# MIMXRT1064 register map
Vendor: nxp.com; File version: 1.0
CPU: CM7 r0p1, little endian, MPU, FPU, VTOR, 4 interrupt priority bits
Registers are 32-bit, read-write, reset 0x0 unless marked. A register's access mark holds for its fields unless they carry their own. Offsets are from the block's base; [hi:lo] are bit positions; {n}, {i} and the like mark numbered series; 'fields as' and 'values as' point back to an identical list.

## SEMC
Base 0x402F0000
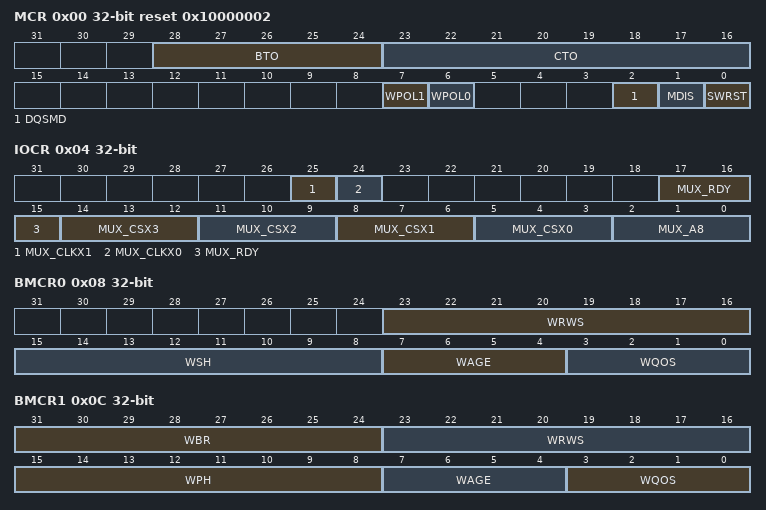
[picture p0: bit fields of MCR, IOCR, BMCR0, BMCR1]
0x00 MCR reset 0x10000002 — Module Control Register
  [28:24] BTO — Bus timeout cycles
    0=255*1; 1=255*2; 31=255*231
  [23:16] CTO — Command Execution timeout cycles
  [7] WPOL1 — R/B# polarity for NAND device
    0=R/B# polarity is not changed; 1=R/B# polarity is inverted
  [6] WPOL0 — WAIT/RDY polarity for SRAM/NOR
    0=WAIT/RDY polarity is not changed; 1=WAIT/RDY polarity is inverted
  [2] DQSMD — DQS (read strobe) mode
    0=Dummy read strobe loopbacked internally; 1=Dummy read strobe loopbacked from DQS pad
  [1] MDIS — Module Disable
    0=Module enabled; 1=Module disabled
  [0] SWRST — Software Reset
    0=No reset; 1=Reset
0x04 IOCR — IO MUX Control Register
  [25] MUX_CLKX1 — SEMC_CLKX1 function selection
    0=NOR clock; 1=SRAM clock
  [24] MUX_CLKX0 — SEMC_CLKX0 function selection
    0=NOR clock; 1=SRAM clock
  [17:15] MUX_RDY — SEMC_RDY function selection
    0=NAND R/B# input; 1=SDRAM CS1; 2=SDRAM CS2; 3=SDRAM CS3; 4=NOR CE#; 5=SRAM CE#; 6=DBI CSX
  [3n+5:3n+3] MUX_CSX{n} (n=0..3) — SEMC_CSX{n} output selection
    1=SDRAM CS1; 2=SDRAM CS2; 3=SDRAM CS3; 4=NAND CE#; 5=NOR CE#; 6=SRAM CE#; 7=DBI CSX
  [2:0] MUX_A8 — SEMC_ADDR08 output selection
    0=SDRAM Address bit 8 (A8) or NOR/SRAM Address bit 24 (A24) in ADMUX 16bit mode; 1=NAND CE#; 2=NOR CE#; 3=SRAM CE#; 4=DBI CSX; 5=SDRAM Address bit 8 (A8) or NOR/SRAM Address bit 24 (A24) in ADMUX 16bit mode; 6=SDRAM Address bit 8 (A8) or NOR/SRAM Address bit 24 (A24) in ADMUX 16bit mode; 7=SDRAM Address bit 8 (A8) or NOR/SRAM Address bit 24 (A24) in ADMUX 16bit mode
0x08 BMCR0 — Bus (AXI) Master Control Register 0
  [23:16] WRWS — Weight of slave hit with Read/Write Switch
  [15:8] WSH — Weight of Slave Hit without read/write switch
  [7:4] WAGE — Weight of AGE
  [3:0] WQOS — Weight of QOS
0x0C BMCR1 — Bus (AXI) Master Control Register 1
  [31:24] WBR — Weight of Bank Rotation
  [23:16] WRWS — Weight of slave hit without Read/Write Switch
  [15:8] WPH — Weight of Page Hit
  [7:4] WAGE — Weight of AGE
  [3:0] WQOS — Weight of QOS
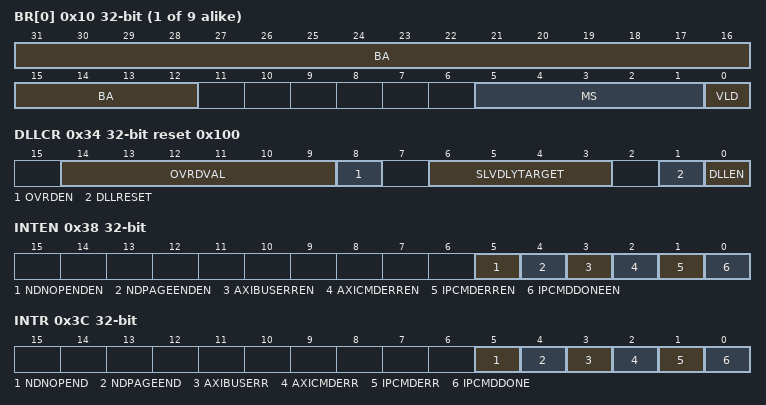
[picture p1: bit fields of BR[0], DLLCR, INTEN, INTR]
{0x10+4i} BR[{i}] (i=0..8) — Base Register n
  [31:12] BA — Base Address
  [5:1] MS — Memory size
    0=4KB; 1=8KB; 2=16KB; 3=32KB; 4=64KB; 5=128KB; 6=256KB; 7=512KB; 8=1MB; 9=2MB; 10=4MB; 11=8MB; 12=16MB; 13=32MB; 14=64MB; 15=128MB; 16=256MB; 17=512MB; 18=1GB; 19=2GB; {v}=4GB (v=20..31)
  [0] VLD — Valid
    0=The memory is invalid, can not be accessed; 1=The memory is valid, can be accessed
0x34 DLLCR reset 0x100 — DLL Control Register
  [14:9] OVRDVAL — Override Value
  [8] OVRDEN — Override Enable
    0=The delay cell number is not overridden; 1=The delay cell number is overridden
  [6:3] SLVDLYTARGET — Delay Target for Slave
  [1] DLLRESET
    0=DLL is not reset; 1=DLL is reset
  [0] DLLEN — DLL calibration enable
    0=DLL calibration is disabled; 1=DLL calibration is enabled
0x38 INTEN — Interrupt Enable Register
  [all] fields
    0=Interrupt is disabled; 1=Interrupt is enabled
  [5] NDNOPENDEN — NAND no pending AXI access interrupt enable
  [4] NDPAGEENDEN — NAND page end interrupt enable
  [3] AXIBUSERREN — AXI bus error interrupt enable
  [2] AXICMDERREN — AXI command error interrupt enable
  [1] IPCMDERREN — IP command error interrupt enable
  [0] IPCMDDONEEN — IP command done interrupt enable
0x3C INTR write-1-clears — Interrupt Register
  [5] NDNOPEND write-1-clears — NAND no pending AXI write transaction interrupt
    0=At least one NAND AXI write transaction is pending or no NAND write transaction is sent to the queue; 1=All NAND AXI write pending transactions are finished
  [4] NDPAGEEND write-1-clears — NAND page end interrupt
    0=The last address of main space in the NAND is not written by AXI command; 1=The last address of main space in the NAND is written by AXI command
  [3] AXIBUSERR write-1-clears — AXI bus error interrupt
    0=No AXI bus error; 1=AXI bus error occurs
  [2] AXICMDERR write-1-clears — AXI command error interrupt
    0=No AXI command error; 1=AXI command error occurs
  [1] IPCMDERR write-1-clears — IP command error done interrupt
    0=No IP command error; 1=IP command error occurs
  [0] IPCMDDONE write-1-clears — IP command normal done interrupt
    0=IP command is not done; 1=IP command is done
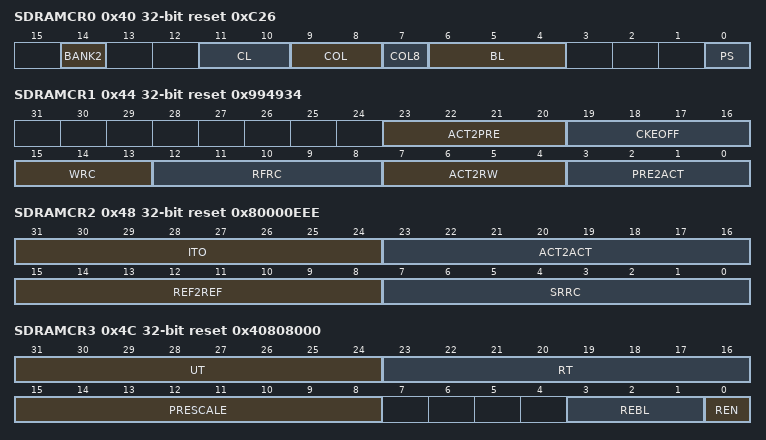
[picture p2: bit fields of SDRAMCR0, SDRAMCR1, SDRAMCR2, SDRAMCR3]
0x40 SDRAMCR0 reset 0xC26 — SDRAM Control Register 0
  [14] BANK2 — 2 Bank selection bit
    0=SDRAM device has 4 banks; 1=SDRAM device has 2 banks
  [11:10] CL — CAS Latency
    0=1; 1=1; 2=2; 3=3
  [9:8] COL — Column address bit number
    0=12; 1=11; 2=10; 3=9
  [7] COL8 — Column 8 selection
    0=Column address bit number is decided by COL field; 1=Column address bit number is 8. COL field is ignored.
  [6:4] BL — Burst Length
    0=1; 1=2; 2=4; {v}=8 (v=3..7)
  [0] PS — Port Size
    0=8bit; 1=16bit
0x44 SDRAMCR1 reset 0x994934 — SDRAM Control Register 1
  [23:20] ACT2PRE — ACTIVE to PRECHARGE minimum time
  [19:16] CKEOFF — CKE off minimum time
  [15:13] WRC — WRITE recovery time
  [12:8] RFRC — REFRESH recovery time
  [7:4] ACT2RW — ACTIVE to READ/WRITE delay
  [3:0] PRE2ACT — PRECHARGE to ACTIVE/REFRESH command wait time
0x48 SDRAMCR2 reset 0x80000EEE — SDRAM Control Register 2
  [31:24] ITO — SDRAM idle timeout
    0=IDLE timeout period is 256*Prescale period; {v}=IDLE timeout period is ITO*Prescale period (v=1..9)
  [23:16] ACT2ACT — ACTIVE to ACTIVE delay
  [15:8] REF2REF — REFRESH to REFRESH delay
  [7:0] SRRC — SELF REFRESH recovery time
0x4C SDRAMCR3 reset 0x40808000 — SDRAM Control Register 3
  [31:24] UT — Urgent refresh threshold
    0=256*(Prescaler period); {v}=UT*(Prescaler period) (v=1..9)
  [23:16] RT — Refresh timer period
    0=(256+1)*(Prescaler period); {v}=(RT+1)*(Prescaler period) (v=1..9)
  [15:8] PRESCALE — Prescaler period
    0=(256*16+1) clock cycles; {v}=(PRESCALE*16+1) clock cycles (v=1..9)
  [3:1] REBL — Refresh burst length
    {v}={v+1} (v=0..7)
  [0] REN — Refresh enable
    0=The SEMC does not send AUTO REFRESH command automatically; 1=The SEMC sends AUTO REFRESH command automatically
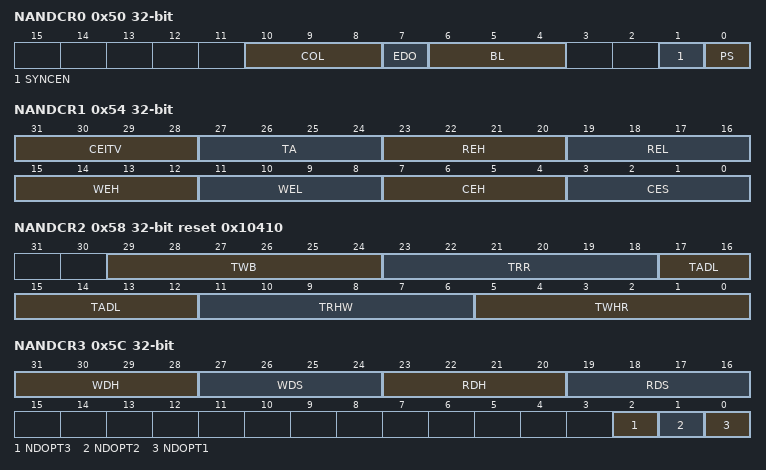
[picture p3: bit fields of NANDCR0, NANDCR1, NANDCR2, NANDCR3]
0x50 NANDCR0 — NAND Control Register 0
  [10:8] COL — Column address bit number
    0=16; 1=15; 2=14; 3=13; 4=12; 5=11; 6=10; 7=9
  [7] EDO — EDO mode enabled
    0=EDO mode disabled; 1=EDO mode enabled
  [6:4] BL — Burst Length
    0=1; 1=2; 2=4; 3=8; 4=16; 5=32; 6=64; 7=64
  [1] SYNCEN — Synchronous Mode Enable
    0=Asynchronous mode is enabled; 1=Synchronous mode is enabled
  [0] PS — Port Size
    0=8bit; 1=16bit
0x54 NANDCR1 — NAND Control Register 1
  [31:28] CEITV — CE# interval time
  [27:24] TA — Turnaround time
  [23:20] REH — RE# high time
  [19:16] REL — RE# low time
  [15:12] WEH — WE# high time
  [11:8] WEL — WE# low time
  [7:4] CEH — CE# hold time
  [3:0] CES — CE# setup time
0x58 NANDCR2 reset 0x10410 — NAND Control Register 2
  [29:24] TWB — WE# high to busy time
  [23:18] TRR — Ready to RE# low time
  [17:12] TADL — Address cycle to data loading time
  [11:6] TRHW — RE# high to WE# low time
  [5:0] TWHR — WE# high to RE# low time
0x5C NANDCR3 — NAND Control Register 3
  [31:28] WDH — Write Data Hold time
  [27:24] WDS — Write Data Setup time
  [23:20] RDH — Read Data Hold time
  [19:16] RDS — Read Data Setup time
  [2] NDOPT3 — NAND option bit 3
  [1] NDOPT2 — NAND option bit 2
  [0] NDOPT1 — NAND option bit 1
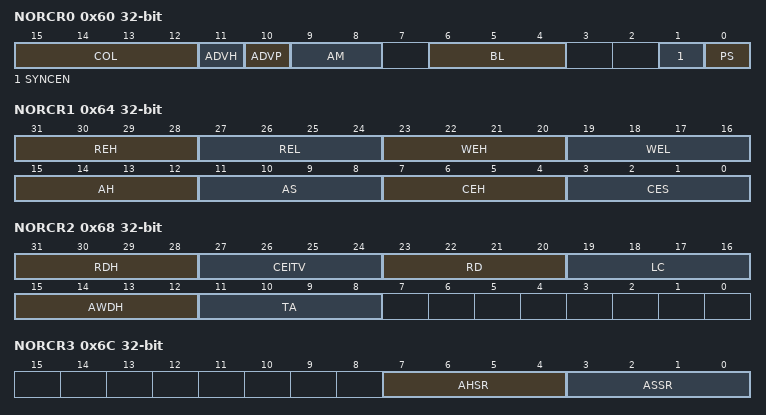
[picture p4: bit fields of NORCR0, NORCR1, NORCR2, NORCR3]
0x60 NORCR0 — NOR Control Register 0
  [15:12] COL — Column Address bit width
    0=12 Bits; 1=11 Bits; 2=10 Bits; 3=9 Bits; 4=8 Bits; 5=7 Bits; 6=6 Bits; 7=5 Bits; 8=4 Bits; 9=3 Bits; 10=2 Bits; {v}=12 Bits (v=11..15)
  [11] ADVH — ADV# level control during address hold state
    0=ADV# is high during address hold state; 1=ADV# is low during address hold state
  [10] ADVP — ADV# Polarity
    0=ADV# is active low; 1=ADV# is active high
  [9:8] AM — Address Mode
    0=Address/Data MUX mode (ADMUX); 1=Advanced Address/Data MUX mode (AADM)
  [6:4] BL — Burst Length
    0=1; 1=2; 2=4; 3=8; 4=16; 5=32; 6=64; 7=64
  [1] SYNCEN — Synchronous Mode Enable
    0=Asynchronous mode is enabled; 1=Synchronous mode is enabled. Only fixed latency mode is supported.
  [0] PS — Port Size
    0=8bit; 1=16bit
0x64 NORCR1 — NOR Control Register 1
  [31:28] REH — RE high time
  [27:24] REL — RE low time
  [23:20] WEH — WE high time
  [19:16] WEL — WE low time
  [15:12] AH — Address hold time
  [11:8] AS — Address setup time
  [7:4] CEH — CE hold time
  [3:0] CES — CE setup time
0x68 NORCR2 — NOR Control Register 2
  [31:28] RDH — Read hold time
  [27:24] CEITV — CE# interval time
  [23:20] RD — Read time
  [19:16] LC — Latency count
  [15:12] AWDH — Address to write data hold time
  [11:8] TA — Turnaround time
0x6C NORCR3 — NOR Control Register 3
  [7:4] AHSR — Address hold time for SYNC read
  [3:0] ASSR — Address setup time for SYNC read
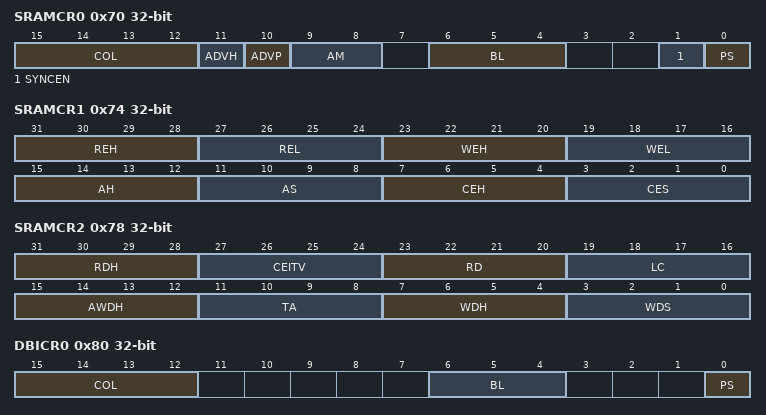
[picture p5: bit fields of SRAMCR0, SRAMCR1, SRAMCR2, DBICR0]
0x70 SRAMCR0 — SRAM Control Register 0
  [15:12] COL — Column Address bit width
    values as NORCR0.COL
  [11] ADVH — ADV# level control during address hold state
    values as NORCR0.ADVH
  [10] ADVP — ADV# polarity
    0=ADV# is active low; 1=ADV# is active high
  [9:8] AM — Address Mode
    values as NORCR0.AM
  [6:4] BL — Burst Length
    0=1; 1=2; 2=4; 3=8; 4=16; 5=32; 6=64; 7=64
  [1] SYNCEN — Synchronous Mode Enable
    values as NORCR0.SYNCEN
  [0] PS — Port Size
    0=8bit; 1=16bit
0x74 SRAMCR1 — SRAM Control Register 1
  fields as NORCR1
0x78 SRAMCR2 — SRAM Control Register 2
  [31:28] RDH — Read hold time
  [27:24] CEITV — CE# interval time
  [23:20] RD — Read time
  [19:16] LC — Latency count
  [15:12] AWDH — Address to write data hold time
  [11:8] TA — Turnaround time
  [7:4] WDH — Write Data hold time
  [3:0] WDS — Write Data setup time
0x7C SRAMCR3 — SRAM Control Register 3
0x80 DBICR0 — DBI-B Control Register 0
  [15:12] COL — Column Address bit width
    values as NORCR0.COL
  [6:4] BL — Burst Length
    0=1; 1=2; 2=4; 3=8; 4=16; 5=32; 6=64; 7=64
  [0] PS — Port Size
    0=8bit; 1=16bit
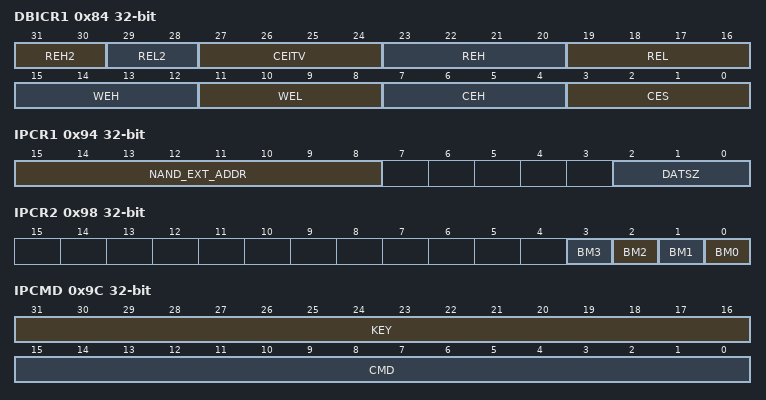
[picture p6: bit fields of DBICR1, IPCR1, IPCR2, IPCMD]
0x84 DBICR1 — DBI-B Control Register 1
  [31:30] REH2 — RDX High Time bit [5:4]
  [29:28] REL2 — RDX Low Time bit [5:4]
  [27:24] CEITV — CSX interval time
  [23:20] REH — RDX High Time bit [3:0]
  [19:16] REL — RDX Low Time bit [3:0]
  [15:12] WEH — WRX High Time
  [11:8] WEL — WRX Low Time
  [7:4] CEH — CSX Hold Time
  [3:0] CES — CSX Setup Time
0x90 IPCR0 — IP Command Control Register 0
  [31:0] SA — Slave address
0x94 IPCR1 — IP Command Control Register 1
  [15:8] NAND_EXT_ADDR — NAND Extended Address
  [2:0] DATSZ — Data Size in Byte
    0=4; {v}={v} (v=1..4); 5=4; 6=4; 7=4
0x98 IPCR2 — IP Command Control Register 2
  [all] fields
    0=Byte is unmasked; 1=Byte is masked
  [n] BM{n} (n=0..3) — Byte Mask for Byte {n} (IPTXDAT bit {8n+7}:{8n})
0x9C IPCMD — IP Command Register
  [31:16] KEY wo — This field should be written with 0xA55A when trigging an IP command for all device types
  [15:0] CMD — SDRAM Commands: 0x8: Read 0x9: Write 0xA: Mode Register Set 0xB: Active 0xC: Auto Refresh 0xD: Self Refresh 0xE: Precharge 0xF: Precharge All Others: Reserved Self Refresh is sent to all SDRAM devices because they share the same SEMC_CLK pin
0xA0 IPTXDAT — TX DATA Register
  [31:0] DAT — Data value to use for an IP write command
0xB0 IPRXDAT ro — RX DATA Register
  [31:0] DAT — Data returned by device for an IP read command.
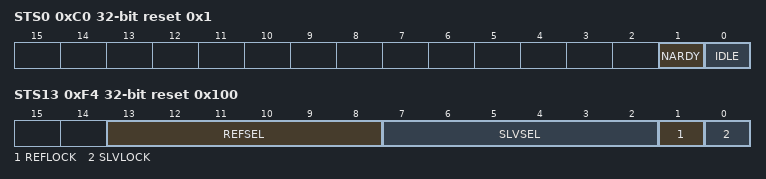
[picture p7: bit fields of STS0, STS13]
0xC0 STS0 ro reset 0x1 — Status Register 0
  [1] NARDY — Indicating NAND device Ready/WAIT# pin level.
    0=NAND device is not ready; 1=NAND device is ready
  [0] IDLE — Indicating whether the SEMC is in idle state.
0xC4 STS1 ro — Status Register 1
0xC8 STS2 ro — Status Register 2
  [3] NDWRPEND — This field indicating whether there is pending AXI command (write) to NAND device.
    0=No pending; 1=Pending
{0xC0+4i} STS{i} ro (i=3..11) — Status Register {i}
0xF0 STS12 ro — Status Register 12
  [31:0] NDADDR — This field indicating the last write address (AXI command) to NAND device (without base address in SEMC_BR4).
0xF4 STS13 ro reset 0x100 — Status Register 13
  [13:8] REFSEL — Sample clock reference delay line delay cell number selection.
  [7:2] SLVSEL — Sample clock slave delay line delay cell number selection.
  [1] REFLOCK — Sample clock reference delay line locked.
    0=Reference delay line is not locked; 1=Reference delay line is locked
  [0] SLVLOCK — Sample clock slave delay line locked.
    0=Slave delay line is not locked; 1=Slave delay line is locked
0xF8 STS14 ro — Status Register 14
0xFC STS15 ro — Status Register 15
